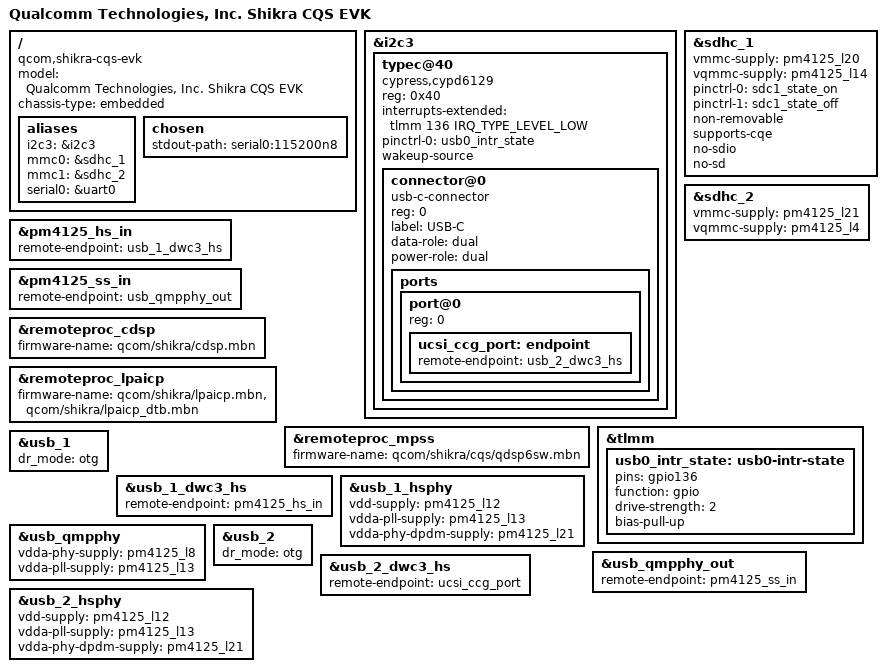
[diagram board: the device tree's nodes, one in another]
// SPDX-License-Identifier: BSD-3-Clause
/*
 * Copyright (c) Qualcomm Technologies, Inc. and/or its subsidiaries.
 */

/dts-v1/;

#include "shikra-cqm-som.dtsi"
#include "shikra-evk.dtsi"
#include <dt-bindings/gpio/gpio.h>

/ {
	model = "Qualcomm Technologies, Inc. Shikra CQS EVK";
	compatible = "qcom,shikra-cqs-evk", "qcom,shikra-cqs-som", "qcom,shikra";
	chassis-type = "embedded";

	aliases {
		i2c3 = &i2c3;
		mmc0 = &sdhc_1;
		mmc1 = &sdhc_2; /* SDC2 SD card slot */
		serial0 = &uart0;
	};

	chosen {
		stdout-path = "serial0:115200n8";
	};
};

&i2c3 {
	status = "okay";

	typec@40 {
		compatible = "cypress,cypd6129";
		reg = <0x40>;
		interrupts-extended = <&tlmm 136 IRQ_TYPE_LEVEL_LOW>;
		pinctrl-0 = <&usb0_intr_state>;
		pinctrl-names = "default";
		wakeup-source;

		#address-cells = <1>;
		#size-cells = <0>;

		connector@0 {
			compatible = "usb-c-connector";
			reg = <0>;
			label = "USB-C";
			data-role = "dual";
			power-role = "dual";

			ports {
				#address-cells = <1>;
				#size-cells = <0>;

				port@0 {
					reg = <0>;

					ucsi_ccg_port: endpoint {
						remote-endpoint = <&usb_2_dwc3_hs>;
					};
				};
			};
		};
	};
};

&pm4125_hs_in {
	remote-endpoint = <&usb_1_dwc3_hs>;
};

&pm4125_ss_in {
	remote-endpoint = <&usb_qmpphy_out>;
};

&remoteproc_cdsp {
	firmware-name = "qcom/shikra/cdsp.mbn";

	status = "okay";
};

&remoteproc_lpaicp {
	firmware-name = "qcom/shikra/lpaicp.mbn",
			"qcom/shikra/lpaicp_dtb.mbn";

	status = "okay";
};

&remoteproc_mpss {
	firmware-name = "qcom/shikra/cqs/qdsp6sw.mbn";

	status = "okay";
};

&sdhc_1 {
	vmmc-supply = <&pm4125_l20>;
	vqmmc-supply = <&pm4125_l14>;

	pinctrl-0 = <&sdc1_state_on>;
	pinctrl-1 = <&sdc1_state_off>;
	pinctrl-names = "default", "sleep";

	non-removable;
	supports-cqe;
	no-sdio;
	no-sd;

	status = "okay";
};

&sdhc_2 {
	vmmc-supply = <&pm4125_l21>;
	vqmmc-supply = <&pm4125_l4>;

	status = "okay";
};

&tlmm {
	usb0_intr_state: usb0-intr-state {
		pins = "gpio136";
		function = "gpio";
		drive-strength = <2>;
		bias-pull-up;
	};
};

&usb_1 {
	dr_mode = "otg";
};

&usb_1_dwc3_hs {
	remote-endpoint = <&pm4125_hs_in>;
};

&usb_1_hsphy {
	vdd-supply = <&pm4125_l12>;
	vdda-pll-supply = <&pm4125_l13>;
	vdda-phy-dpdm-supply = <&pm4125_l21>;

	status = "okay";
};

&usb_qmpphy {
	vdda-phy-supply = <&pm4125_l8>;
	vdda-pll-supply = <&pm4125_l13>;

	status = "okay";
};

&usb_qmpphy_out {
	remote-endpoint = <&pm4125_ss_in>;
};

&usb_2 {
	dr_mode = "otg";
};

&usb_2_dwc3_hs {
	remote-endpoint = <&ucsi_ccg_port>;
};

&usb_2_hsphy {
	vdd-supply = <&pm4125_l12>;
	vdda-pll-supply = <&pm4125_l13>;
	vdda-phy-dpdm-supply = <&pm4125_l21>;

	status = "okay";
};
